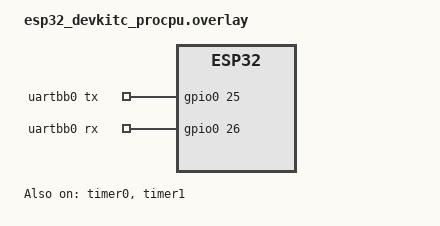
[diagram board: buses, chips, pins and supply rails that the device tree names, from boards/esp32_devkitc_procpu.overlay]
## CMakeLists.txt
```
# SPDX-License-Identifier: Apache-2.0

cmake_minimum_required(VERSION 3.28.0)
find_package(Zephyr REQUIRED HINTS $ENV{ZEPHYR_BASE})
project(passthrough)

target_sources(app PRIVATE src/main.c)
```

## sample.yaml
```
sample:
  name: UART Passthrough
tests:
  sample.drivers.uart.passthrough:
    platform_allow:
      - nucleo_l476rg
    tags:
      - serial
      - uart
    harness: keyboard
```

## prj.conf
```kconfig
CONFIG_SERIAL=y
CONFIG_UART_INTERRUPT_DRIVEN=y
```

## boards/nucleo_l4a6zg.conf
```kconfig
# Copyright (c) 2025 Joel Guittet
# SPDX-License-Identifier: Apache-2.0

CONFIG_UART_BITBANG=y
```

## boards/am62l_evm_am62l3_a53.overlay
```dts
/*
 * Copyright (c) 2026 Texas Instruments
 *
 * SPDX-License-Identifier: Apache-2.0
 */

/ {
	chosen {
		uart,passthrough = &main_uart0;
	};
};

&main_uart0 {
	status = "okay";
};
```

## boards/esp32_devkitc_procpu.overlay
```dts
/*
 * Copyright (c) 2025 Joel Guittet
 * SPDX-License-Identifier: Apache-2.0
 */

/ {
	chosen {
		uart,passthrough = &uartbb0;
	};

	uartbb0: uartbb0 {
		compatible = "zephyr,uart-bitbang";
		tx-gpios = <&gpio0 25 GPIO_ACTIVE_HIGH>;
		rx-gpios = <&gpio0 26 GPIO_ACTIVE_HIGH>;
		current-speed = <19200>;
		data-bits = <8>;
		stop-bits = "1";
		parity = "none";
		tx-timer = <&timer0>;
		rx-timer = <&timer1>;
		status = "okay";
	};
};

&timer0 {
	status = "okay";

	counter {
		status = "okay";
	};
};

&timer1 {
	status = "okay";

	counter {
		status = "okay";
	};
};
```

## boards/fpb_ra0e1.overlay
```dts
/*
 * Copyright (c) 2026 Renesas Electronics Corporation
 * SPDX-License-Identifier: Apache-2.0
 */

/ {
	chosen {
		uart,passthrough = &uart2;
	};
};

&uart2 {
	status = "okay";
};
```

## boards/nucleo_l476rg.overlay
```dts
/*
 * SPDX-FileCopyrightText: Copyright The Zephyr Project Contributors
 * SPDX-License-Identifier: Apache-2.0
 */

/ {
	chosen {
		uart,passthrough = &uart4;
	};
};

&uart4 {
	pinctrl-0 = <&uart4_tx_pa0 &uart4_rx_pa1>;
	pinctrl-names = "default";
	current-speed = <9600>;
	status = "okay";
};
```

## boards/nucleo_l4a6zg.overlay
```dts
/*
 * Copyright (c) 2025 Joel Guittet
 * SPDX-License-Identifier: Apache-2.0
 */

/ {
	chosen {
		uart,passthrough = &uartbb0;
	};

	uartbb0: uartbb0 {
		compatible = "zephyr,uart-bitbang";
		tx-gpios = <&gpiod 0 GPIO_ACTIVE_HIGH>;
		rx-gpios = <&gpiod 1 GPIO_ACTIVE_HIGH>;
		current-speed = <19200>;
		data-bits = <8>;
		stop-bits = "1";
		parity = "none";
		tx-timer = <&timers6>;
		rx-timer = <&timers7>;
		status = "okay";
	};
};

&timers6 {
	status = "okay";
	counter {
		status = "okay";
	};
};

&timers7 {
	status = "okay";
	counter {
		status = "okay";
	};
};
```

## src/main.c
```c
/*
 * Copyright (c) 2024 Argentum Systems Ltd.
 *
 * SPDX-License-Identifier: Apache-2.0
 */

#include <zephyr/kernel.h>
#include <zephyr/device.h>
#include <zephyr/drivers/uart.h>
#include <zephyr/sys/ring_buffer.h>

#include <stdio.h>
#include <string.h>

struct patch_info {
	const uint8_t * const name;

	const struct device *rx_dev;
	struct ring_buf *rx_ring_buf;
	bool rx_error;
	bool rx_overflow;

	const struct device *tx_dev;
};

#define DEV_CONSOLE DEVICE_DT_GET(DT_CHOSEN(zephyr_console))
#define DEV_OTHER   DEVICE_DT_GET(DT_CHOSEN(uart_passthrough))

#define RING_BUF_SIZE 64

RING_BUF_DECLARE(rb_console, RING_BUF_SIZE);
struct patch_info patch_c2o = {
	.name = "c2o",

	.rx_dev = DEV_CONSOLE,
	.rx_ring_buf = &rb_console,
	.rx_error = false,
	.rx_overflow = false,

	.tx_dev = DEV_OTHER,
};

RING_BUF_DECLARE(rb_other, RING_BUF_SIZE);
struct patch_info patch_o2c = {
	.name = "o2c",

	.rx_dev = DEV_OTHER,
	.rx_ring_buf = &rb_other,
	.rx_error = false,
	.rx_overflow = false,

	.tx_dev = DEV_CONSOLE,
};

static void uart_cb(const struct device *dev, void *ctx)
{
	struct patch_info *patch = (struct patch_info *)ctx;
	int ret;
	uint8_t *buf;
	uint32_t len;

	while (true) {
		uart_irq_update(patch->rx_dev);

		ret = uart_irq_rx_ready(patch->rx_dev);
		if (ret < 0) {
			patch->rx_error = true;
		}
		if (ret <= 0) {
			break;
		}

		len = ring_buf_put_ptr(patch->rx_ring_buf, &buf, 0);
		if (len == 0) {
			/* no space for Rx, disable the IRQ */
			uart_irq_rx_disable(patch->rx_dev);
			patch->rx_overflow = true;
			break;
		}

		ret = uart_fifo_read(patch->rx_dev, buf, len);
		if (ret < 0) {
			patch->rx_error = true;
		}
		if (ret <= 0) {
			break;
		}
		len = ret;

		ring_buf_commit(patch->rx_ring_buf, len);
	}
}

static void passthrough(struct patch_info *patch)
{
	int ret;
	uint8_t *buf;
	uint32_t len;

	if (patch->rx_error) {
		printk("<<%s: Rx Error!>>\n", patch->name);
		patch->rx_error = false;
	}

	if (patch->rx_overflow) {
		printk("<<%s: Rx Overflow!>>\n", patch->name);
		patch->rx_overflow = false;
	}

	len = ring_buf_get_ptr(patch->rx_ring_buf, &buf, 0);
	if (len == 0) {
		goto done;
	}

	ret = uart_fifo_fill(patch->tx_dev, buf, len);
	if (ret < 0) {
		goto error;
	}
	len = ret;

	ring_buf_consume(patch->rx_ring_buf, len);
done:
	uart_irq_rx_enable(patch->rx_dev);
	return;

error:
	printk("<<%s: Tx Error!>>\n", patch->name);
}

int main(void)
{
	printk("Console Device: %p\n", patch_c2o.rx_dev);
	printk("Other Device:   %p\n", patch_o2c.rx_dev);

	uart_irq_callback_user_data_set(patch_c2o.rx_dev, uart_cb, (void *)&patch_c2o);
	uart_irq_callback_user_data_set(patch_o2c.rx_dev, uart_cb, (void *)&patch_o2c);

	for (;;) {
		passthrough(&patch_c2o);
		passthrough(&patch_o2c);
	}

	return 0;
}
```
